# MCXN947_cm33_core0 register map
Vendor: nxp.com; File version: 1.0
CPU: CM33 r2p0, little endian, MPU, FPU, VTOR, 3 interrupt priority bits
Registers are 32-bit, read-write, reset 0x0 unless marked. A register's access mark holds for its fields unless they carry their own. Offsets are from the block's base; [hi:lo] are bit positions; {n}, {i} and the like mark numbered series; 'fields as' and 'values as' point back to an identical list.

## SPC0 — SPC
Base 0x40045000
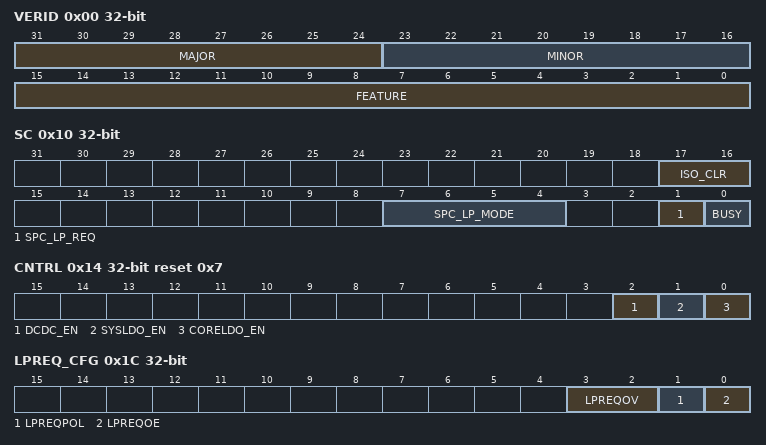
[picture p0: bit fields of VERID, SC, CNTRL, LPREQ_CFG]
0x00 VERID ro — Version ID
  [31:24] MAJOR — Major Version Number
  [23:16] MINOR — Minor Version Number
  [15:0] FEATURE — Feature Specification Number
    0=STANDARD (Standard features)
0x10 SC — Status Control
  [17:16] ISO_CLR write-1-clears — Isolation Clear Flags
  [7:4] SPC_LP_MODE ro — Power Domain Low-Power Mode Request
    0=MODE0 (Sleep mode with system clock running); 1=MODE1 (DSLEEP with system clock off); 2=MODE2 (PDOWN with system clock off); 8=MODE8 (DPDOWN with system clock off)
  [1] SPC_LP_REQ write-1-clears — SPC Power Mode Configuration Status Flag
    on read: 0=ACTIVE (SPC is in Active mode; the ACTIVE_CFG register has control); 1=LOW_POWER (All power domains requested low-power mode; SPC entered a low-power state; power-mode configuration based on the LP_CFG register)
  [0] BUSY ro — SPC Busy Status Flag
    0=BUSY_NO (Not busy); 1=BUSY_YES
0x14 CNTRL rw-once reset 0x7 — SPC Regulator Control
  [all] fields
    0=DISABLE; 1=ENABLE
  [2] DCDC_EN — DCDC_CORE Regulator Enable
  [1] SYSLDO_EN — LDO_SYS Regulator Enable
  [0] CORELDO_EN — LDO_CORE Regulator Enable
0x1C LPREQ_CFG — Low-Power Request Configuration
  [3:2] LPREQOV — Low-Power Request Output Override
    0=FORCE_NO (Not forced); 2=FORCE_LOW (Forced low (ignore LPREQPOL settings)); 3=FORCE_HIGH (Forced high (ignore LPREQPOL settings))
  [1] LPREQPOL — Low-Power Request Output Pin Polarity Control
    0=HIGH; 1=LOW
  [0] LPREQOE — Low-Power Request Output Enable
    0=DISABLE; 1=ENABLE
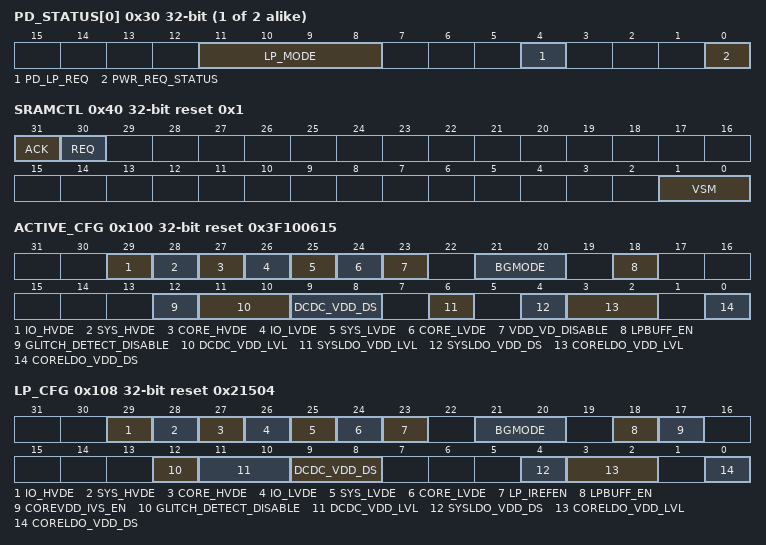
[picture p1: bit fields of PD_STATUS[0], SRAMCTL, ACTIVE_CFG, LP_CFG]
{0x30+4i} PD_STATUS[{i}] (i=0..1) — SPC Power Domain Mode Status
  [11:8] LP_MODE ro — Power Domain Low Power Mode Request
    0=MODE0 (SLEEP with system clock running); 1=MODE1 (DSLEEP with system clock off); 2=MODE2 (PDOWN with system clock off); 8=MODE8 (DPDOWN with system clock off)
  [4] PD_LP_REQ write-1-clears — Power Domain Low Power Request Flag
    0=REQ_NO (Did not request); 1=REQ_YES (Requested)
  [0] PWR_REQ_STATUS ro — Power Request Status Flag
    0=REQ_NO (Did not request); 1=REQ_YES (Requested)
0x40 SRAMCTL reset 0x1 — SRAM Control
  [31] ACK ro — SRAM Voltage Update Request Acknowledge
    0=ACK_NO (Not acknowledged); 1=ACK_YES (Acknowledged)
  [30] REQ — SRAM Voltage Update Request
    0=REQ_NO (Do not request); 1=REQ_YES (Request)
  [1:0] VSM — Voltage Select Margin
    1=1.0 V; 2=1.1 V; 3=SRAM configured for 1.2 V operation
0x100 ACTIVE_CFG reset 0x3F100615 — Active Power Mode Configuration
  [29] IO_HVDE — IO High-Voltage Detection Enable
    0=DISABLE; 1=ENABLE
  [28] SYS_HVDE — System High-Voltage Detection Enable
    0=DISABLE; 1=ENABLE
  [27] CORE_HVDE — Core High-Voltage Detection Enable
    0=DISABLE; 1=ENABLE
  [26] IO_LVDE — IO Low-Voltage Detection Enable
    0=DISABLE; 1=ENABLE
  [25] SYS_LVDE — System Low-Voltage Detection Enable
    0=DISABLE; 1=ENABLE
  [24] CORE_LVDE — Core Low-Voltage Detection Enable
    0=DISABLE; 1=ENABLE
  [23] VDD_VD_DISABLE — VDD Voltage Detect Disable
    0=ENABLE; 1=DISABLE
  [21:20] BGMODE — Bandgap Mode
    0=Bandgap disabled; 1=Bandgap enabled, buffer disabled; 2=Bandgap enabled, buffer enabled
  [18] LPBUFF_EN — CMP Bandgap Buffer Enable
    0=DISABLE; 1=ENABLE
  [12] GLITCH_DETECT_DISABLE — VDD Core Glitch Detect Disable
    0=DISABLED (VDD Core Low Voltage Glitch Detect enabled); 1=ENABLED (VDD Core Low Voltage Glitch Detect disabled)
  [11:10] DCDC_VDD_LVL — DCDC VDD Regulator Voltage Level
    1=DCDC01 (Midvoltage (1.0 V)); 2=DCDC10 (Normal voltage (1.1 V)); 3=DCDC11 (Overdrive voltage (1.2 V))
  [9:8] DCDC_VDD_DS — DCDC VDD Drive Strength
    1=LOW; 2=NORMAL
  [6] SYSLDO_VDD_LVL — LDO_SYS VDD Regulator Voltage Level
    0=NORMAL (Normal voltage (1.8 V)); 1=OVER (Overdrive voltage (2.5 V))
  [4] SYSLDO_VDD_DS — LDO_SYS VDD Drive Strength
    0=LOW; 1=NORMAL
  [3:2] CORELDO_VDD_LVL — LDO_CORE VDD Regulator Voltage Level
    1=MID (Regulate to mid voltage (1.0 V)); 2=NORMAL (Regulate to normal voltage (1.1 V)); 3=OVER (Regulate to overdrive voltage (1.2 V))
  [0] CORELDO_VDD_DS — LDO_CORE VDD Drive Strength
    0=LOW; 1=NORMAL
0x104 ACTIVE_CFG1 reset 0x2 — Active Power Mode Configuration 1
  [31:0] SOC_CNTRL — Active Config Chip Control
0x108 LP_CFG reset 0x21504 — Low-Power Mode Configuration
  [29] IO_HVDE — IO High Voltage Detect Enable
    0=DISABLE; 1=ENABLE
  [28] SYS_HVDE — System High Voltage Detect Enable
    0=DISABLE; 1=ENABLE
  [27] CORE_HVDE — Core High Voltage Detect Enable
    0=DISABLE; 1=ENABLE
  [26] IO_LVDE — IO Low Voltage Detect Enable
    0=DISABLE; 1=ENABLE
  [25] SYS_LVDE — System Low Voltage Detect Enable
    0=DISABLE; 1=ENABLE
  [24] CORE_LVDE — Core Low Voltage Detect Enable
    0=DISABLE; 1=ENABLE
  [23] LP_IREFEN — Low-Power IREF Enable
    0=DISABLE (Disable for power saving in Deep Power Down mode); 1=ENABLE
  [21:20] BGMODE — Bandgap Mode
    values as ACTIVE_CFG.BGMODE
  [18] LPBUFF_EN — CMP Bandgap Buffer Enable
    0=DISABLE; 1=ENABLE
  [17] COREVDD_IVS_EN — CORE VDD Internal Voltage Scaling (IVS) Enable
    0=DISABLE; 1=ENABLE
  [12] GLITCH_DETECT_DISABLE — VDD Core Glitch Detect Disable
    0=ENABLE; 1=DISABLE
  [11:10] DCDC_VDD_LVL — DCDC VDD Regulator Voltage Level
    0=VDD00; 1=VDD01 (Mid voltage (1.0 V)); 2=VDD10 (Normal voltage (1.1 V)); 3=VDD11 (Overdrive voltage (1.2 V))
  [9:8] DCDC_VDD_DS — DCDC VDD Drive Strength
    0=PULSE (Pulse refresh); 1=LOW; 2=NORMAL
  [4] SYSLDO_VDD_DS — LDO_SYS VDD Drive Strength
    0=LOW; 1=NORMAL
  [3:2] CORELDO_VDD_LVL — LDO_CORE VDD Regulator Voltage Level
    0=UNDER (Under voltage (0.95 V)); 1=MID (Mid voltage (1.0 V)); 2=NORMAL (Normal voltage (1.1 V)); 3=OVER (Overdrive voltage (1.2 V))
  [0] CORELDO_VDD_DS — LDO_CORE VDD Drive Strength
    0=LOW; 1=NORMAL
0x10C LP_CFG1 reset 0x2 — Low Power Mode Configuration 1
  [31:0] SOC_CNTRL — Low-Power Configuration Chip Control
0x120 LPWKUP_DELAY — Low Power Wake-Up Delay
  [15:0] LPWKUP_DELAY — Low-Power Wake-Up Delay
0x124 ACTIVE_VDELAY reset 0xC8 — Active Voltage Trim Delay
  [15:0] ACTIVE_VDELAY — Active Voltage Delay
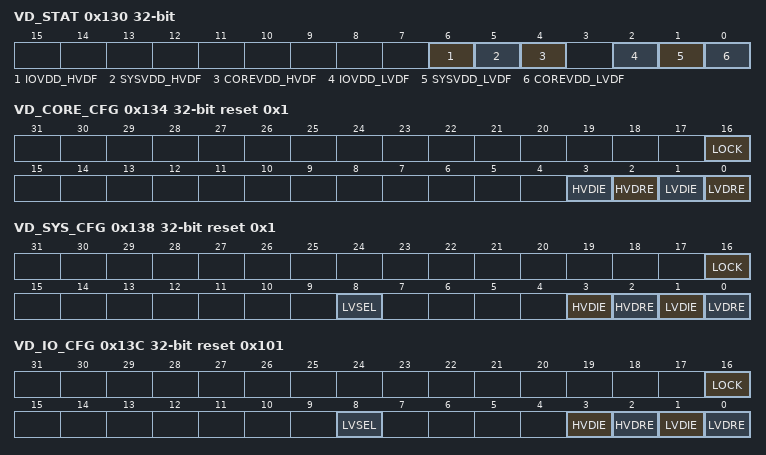
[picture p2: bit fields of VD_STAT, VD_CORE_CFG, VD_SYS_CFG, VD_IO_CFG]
0x130 VD_STAT write-1-clears — Voltage Detect Status
  [all] fields
    on read: 0=EVENT_NO (Event not detected); 1=EVENT_YES (Event detected)
  [6] IOVDD_HVDF write-1-clears — IO VDD HVD Flag
  [5] SYSVDD_HVDF write-1-clears — System VDD HVD Flag
  [4] COREVDD_HVDF write-1-clears — Core VDD HVD Flag
  [2] IOVDD_LVDF write-1-clears — IO VDD LVD Flag
  [1] SYSVDD_LVDF write-1-clears — System VDD Low-Voltage Detect Flag
  [0] COREVDD_LVDF write-1-clears — Core VDD Low-Voltage Detect Flag
0x134 VD_CORE_CFG reset 0x1 — Core Voltage Detect Configuration
  [16] LOCK — Core Voltage Detect Reset Enable Lock
    0=ALLOW; 1=DENY
  [3] HVDIE — Core VDD HVD Interrupt Enable
    0=DISABLE; 1=ENABLE
  [2] HVDRE — Core VDD HVD Reset Enable
    0=DISABLE; 1=ENABLE
  [1] LVDIE — Core VDD LVD Interrupt Enable
    0=DISABLE; 1=ENABLE
  [0] LVDRE — Core VDD LVD Reset Enable
    0=DISABLE; 1=ENABLE
0x138 VD_SYS_CFG reset 0x1 — System Voltage Detect Configuration
  [16] LOCK — System Voltage Detect Reset Enable Lock
    0=ALLOW; 1=DENY
  [8] LVSEL — System VDD Low-Voltage Level Select
    0=NORMAL; 1=SAFE
  [3] HVDIE — System VDD HVD Interrupt Enable
    0=DISABLE; 1=ENABLE
  [2] HVDRE — System VDD HVD Reset Enable
    0=DISABLE; 1=ENABLE
  [1] LVDIE — System VDD LVD Interrupt Enable
    0=DISABLE; 1=ENABLE
  [0] LVDRE — System VDD LVD Reset Enable
    0=DISABLE; 1=ENABLE
0x13C VD_IO_CFG reset 0x101 — IO Voltage Detect Configuration
  [16] LOCK — IO Voltage Detect Reset Enable Lock
    0=ALLOW; 1=DENY
  [8] LVSEL — IO VDD Low-Voltage Level Select
    0=NORMAL; 1=SAFE
  [3] HVDIE — IO VDD HVD Interrupt Enable
    0=DISABLE; 1=ENABLE
  [2] HVDRE — IO VDD HVD Reset Enable
    0=DISABLE; 1=ENABLE
  [1] LVDIE — IO VDD LVD Interrupt Enable
    0=DISABLE; 1=ENABLE
  [0] LVDRE — IO VDD LVD Reset Enable
    0=DISABLE; 1=ENABLE
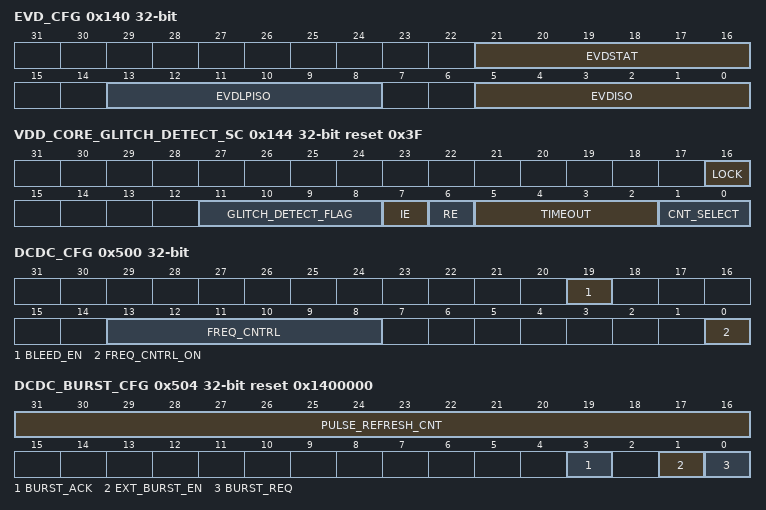
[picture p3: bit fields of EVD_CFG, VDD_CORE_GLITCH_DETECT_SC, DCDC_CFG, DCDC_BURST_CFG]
0x140 EVD_CFG — External Voltage Domain Configuration
  [21:16] EVDSTAT ro — External Voltage Domain Status
  [13:8] EVDLPISO — External Voltage Domain Low-Power Isolation
  [5:0] EVDISO — External Voltage Domain Isolation
0x144 VDD_CORE_GLITCH_DETECT_SC reset 0x3F — VDD Core Glitch Detect Status Control
  [16] LOCK — VDD Core Voltage Glitch Detect Reset Enable Lock Bit
    0=DISABLED (Writes to RE are allowed.); 1=ENABLED (Writes to RE are ignored.)
  [11:8] GLITCH_DETECT_FLAG write-1-clears
  [7] IE — Core VDD Glitch Detect Interrupt Enable
    0=DISABLED (GLITCH_DETECT_FLAG[CNT_SELECT] does not generate hardware interrupt (user polling)); 1=ENABLED (GLITCH_DETECT_FLAG[CNT_SELECT] does generate hardware interrupt)
  [6] RE — Core VDD Glitch Detect Reset Enable
    0=DISABLED (GLITCH_DETECT_FLAG[CNT_SELECT] does not generate POR/LVD reset); 1=ENABLED (GLITCH_DETECT_FLAG[CNT_SELECT] does generate POR/LVD reset)
  [5:2] TIMEOUT
  [1:0] CNT_SELECT — Counter Select
    {v}=BIT{v} ({v}) (v=0..3)
0x300 CORELDO_CFG — LDO_CORE Configuration
  [16] DPDOWN_PULLDOWN_DISABLE — LDO_CORE Deep Power Down Pulldown Disable
    0=DISABLED (LDO_CORE pulldown in Deep Power Down not disabled); 1=ENABLED (LDO_CORE pulldown in Deep Power Down disabled)
0x400 SYSLDO_CFG reset 0x101 — LDO_SYS Configuration
  [0] ISINKEN — Current Sink Enable
    0=DISABLE; 1=ENABLED
0x500 DCDC_CFG — DCDC Configuration
  [19] BLEED_EN — DCDC Bleed Enable
    0=ADD_NO (Do not add); 1=ADD_YES
  [13:8] FREQ_CNTRL — DCDC Burst Frequency Control
  [0] FREQ_CNTRL_ON — DCDC Burst Frequency Control Enable
    0=DISABLE; 1=ENABLE
0x504 DCDC_BURST_CFG reset 0x1400000 — DCDC Burst Configuration
  [31:16] PULSE_REFRESH_CNT — Refresh Count Value
  [3] BURST_ACK write-1-clears — Burst Acknowledge Flag
    on read: 0=COMPL_NO (Did not complete); 1=COMPL_YES (Completed)
  [1] EXT_BURST_EN — External Burst Request Enable
    0=DISABLE; 1=ENABLE
  [0] BURST_REQ — Software Burst Request
    0=GEN_NO (Do not generate); 1=GEN_YES (Generate)
